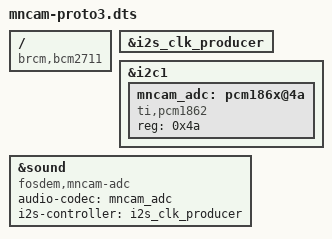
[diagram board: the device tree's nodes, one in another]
/dts-v1/;
/plugin/;

/ {
	compatible = "brcm,bcm2711";


	fragment@0 {
		target = <&i2s_clk_producer>;
		__overlay__ {
			status = "okay";
		};
	};

	fragment@1 {
		target = <&i2c1>;
		__overlay__ {
			#address-cells = <1>;
			#size-cells = <0>;
			status = "okay";

			mncam_adc: pcm186x@4a {
				#sound-dai-cells = <0>;
				compatible = "ti,pcm1862";
				reg = <0x4a>;
				status = "okay";
			};
		};
	};

	fragment@2 {
		target = <&sound>;
		hifiberry_adc: __overlay__ {
			compatible = "fosdem,mncam-adc";
			audio-codec = <&mncam_adc>;
			i2s-controller = <&i2s_clk_producer>;
			status = "okay";
		};
	};
};
